# hercules_cpgmac_tms570ls3x register map
Vendor: Texas Instruments
Peripheral module from a debugger description file (folder hercules).
Registers are 32-bit, access not given, reset 0x0 unless marked. A register's access mark holds for its fields unless they carry their own. Offsets are as the file gives them; lines under a group give offsets from that group; [hi:lo] are bit positions; {n}, {i} and the like mark numbered series; 'fields as' and 'values as' point back to an identical list; <NAME> marks a mode.

## ECTL — Common Platform Gigabit ethernet MAC SubSystem RMII
0x00 REVID ro reset 0x4EC80100 — Transmit Identification and Version Register
  [31:0] REV — REV ID
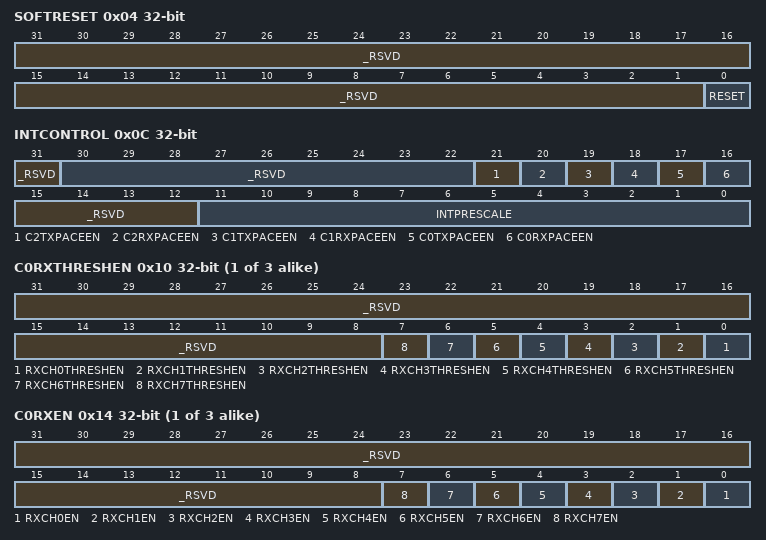
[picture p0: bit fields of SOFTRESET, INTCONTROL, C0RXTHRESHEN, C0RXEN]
0x04 SOFTRESET — Software Reset Register
  [31:1] _RSVD — (access N)
  [0] RESET rw — Soft Reset for CPGMACSS_R modules INT, REGS, CPPI
0x0C INTCONTROL — Interrupt Control Register
  [31] _RSVD — Interrupt Test (access N)
  [30:22] _RSVD — (access N)
  [21] C2TXPACEEN rw — C2_TX_PULSE Pacing
    0=DISABLE; 1=ENABLE
  [20] C2RXPACEEN rw — C2_RX_PULSE Pacing
    0=DISABLE; 1=ENABLE
  [19] C1TXPACEEN rw — C1_TX_PULSE Pacing
    0=DISABLE; 1=ENABLE
  [18] C1RXPACEEN rw — C1_RX_PULSE Pacing
    0=DISABLE; 1=ENABLE
  [17] C0TXPACEEN rw — C0_TX_PULSE Pacing
    0=DISABLE; 1=ENABLE
  [16] C0RXPACEEN rw — C0_RX_PULSE Pacing
    0=DISABLE; 1=ENABLE
  [15:12] _RSVD — (access N)
  [11:0] INTPRESCALE rw — Interrupt Counter Prescaler (Number of 4us VBUSP_CLKs)
{0x10+0x10*i} C{i}RXTHRESHEN (i=0..2) — Core {i} Receive Threshold Enable Register
  [31:8] _RSVD — (access N)
  [n] RXCH{n}THRESHEN rw (n=0..7) — Corresponds to the interrupt for RXCH{n}THRESH
    0=DISABLE; 1=ENABLE
{0x14+0x10*i} C{i}RXEN (i=0..2) — Core {i} Receive Enable Register
  [31:8] _RSVD — (access N)
  [n] RXCH{n}EN rw (n=0..7) — Corresponds to the interrupt for RXCH{n}EN
    0=DISABLE; 1=ENABLE
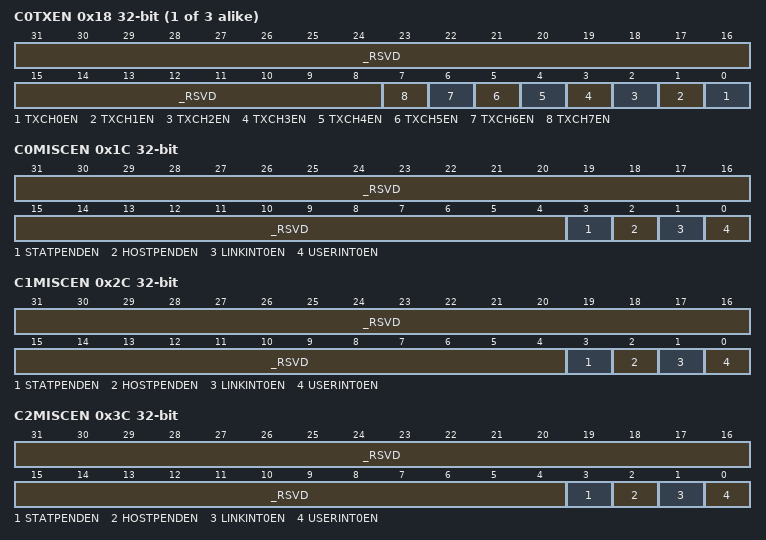
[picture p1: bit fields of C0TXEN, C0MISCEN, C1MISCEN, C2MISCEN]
{0x18+0x10*i} C{i}TXEN (i=0..2) — Core {i} Transmit Enable Register
  [31:8] _RSVD — (access N)
  [n] TXCH{n}EN rw (n=0..7) — Corresponds to the interrupt for TXCH{n}EN
    0=DISABLE; 1=ENABLE
0x1C C0MISCEN — Core 0 Misc Interrupt Enable Register
  [31:4] _RSVD — (access N)
  [3] STATPENDEN rw — Status Pending Interrupt
    0=DISABLE; 1=ENABLE
  [2] HOSTPENDEN rw — Host Pending Interrupt
    0=DISABLE; 1=ENABLE
  [1] LINKINT0EN rw — MDIO LINKINT[0]
    0=DISABLE; 1=ENABLE
  [0] USERINT0EN rw — MDIO USERINT[0]
    0=DISABLE; 1=ENABLE
0x2C C1MISCEN — Core 1 Misc Enable Register
  fields as C0MISCEN
0x3C C2MISCEN — Core 2 Misc Enable Register
  fields as C0MISCEN
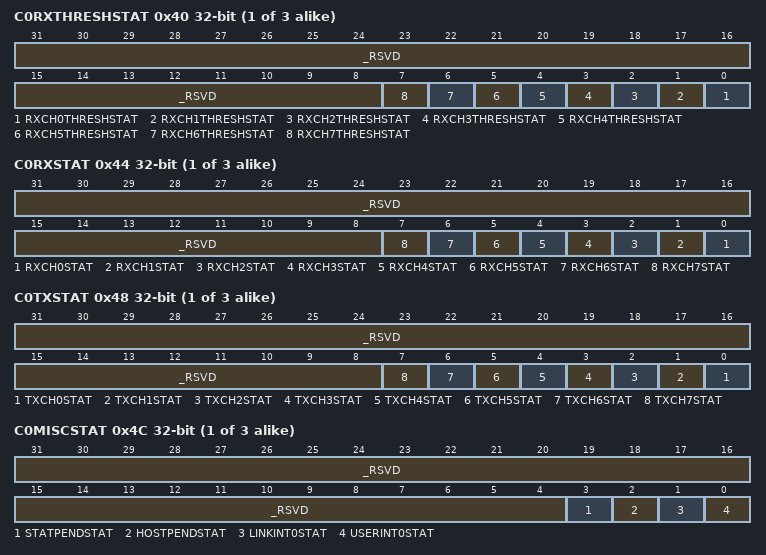
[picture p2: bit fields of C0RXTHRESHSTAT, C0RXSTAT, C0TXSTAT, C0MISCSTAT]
{0x40+0x10*i} C{i}RXTHRESHSTAT (i=0..2) — Core {i} Receive Threshold Status Register
  [31:8] _RSVD — (access N)
  [n] RXCH{n}THRESHSTAT ro (n=0..7) — Corresponds to the interrupt for RXCH{n}THRESH
{0x44+0x10*i} C{i}RXSTAT (i=0..2) — Core {i} Receive Status Register
  [31:8] _RSVD — (access N)
  [n] RXCH{n}STAT ro (n=0..7) — Corresponds to the interrupt for RXCH{n}STAT
{0x48+0x10*i} C{i}TXSTAT (i=0..2) — Core {i} Transmit Status Register
  [31:8] _RSVD — (access N)
  [n] TXCH{n}STAT ro (n=0..7) — Corresponds to the interrupt for TXCH{n}STAT
{0x4C+0x10*i} C{i}MISCSTAT (i=0..2) — Core {i} Misc Interrupt Status Register
  [31:4] _RSVD — (access N)
  [3] STATPENDSTAT ro
  [2] HOSTPENDSTAT ro
  [1] LINKINT0STAT ro
  [0] USERINT0STAT ro
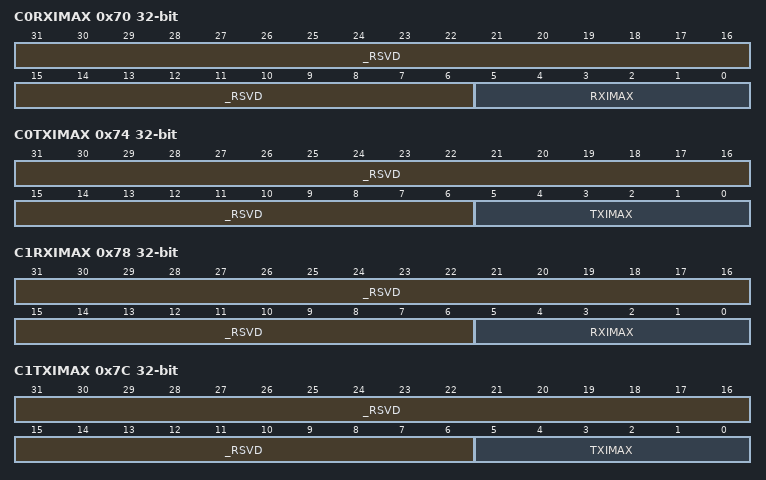
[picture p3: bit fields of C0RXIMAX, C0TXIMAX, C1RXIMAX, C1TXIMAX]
0x70 C0RXIMAX — Core 0 Receive Interrupts per Millisecond Register
  [31:6] _RSVD — (access N)
  [5:0] RXIMAX rw — Core 0 Receive Interrupts per Millisecond for C0RXPULSE
0x74 C0TXIMAX — Core 0 Transmit Interrupts per Millisecond Register
  [31:6] _RSVD — (access N)
  [5:0] TXIMAX rw — Core 0 Receive Interrupts per Millisecond for C0TXPULSE
0x78 C1RXIMAX — Core 1 Receive Interrupts per Millisecond Register
  [31:6] _RSVD — (access N)
  [5:0] RXIMAX rw — Core 1 Receive Interrupts per Millisecond for C1RXPULSE
0x7C C1TXIMAX — Core 1 Transmit Interrupts per Millisecond Register
  [31:6] _RSVD — (access N)
  [5:0] TXIMAX rw — Core 1 Receive Interrupts per Millisecond for C1TXPULSE
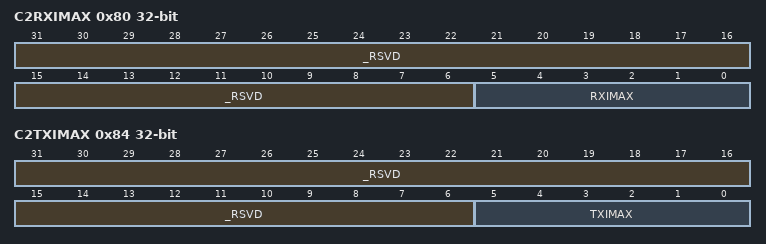
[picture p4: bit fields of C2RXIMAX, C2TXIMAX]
0x80 C2RXIMAX — Core 2 Receive Interrupts per Millisecond Register
  fields as C1RXIMAX
0x84 C2TXIMAX — Core 2 Transmit Interrupts per Millisecond Register
  fields as C1TXIMAX
